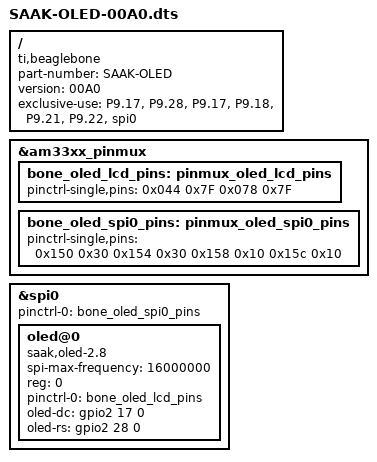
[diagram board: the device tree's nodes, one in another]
/*  
* Copyright (C) 2012 Texas Instruments Incorporated - http://www.ti.com/
*
* This program is free software; you can redistribute it and/or modify
* it under the terms of the GNU General Purpose License Version 2 as
* published by the Free Software Foundation
*
* by Saak Dertadian (s.dertadian@gmail.com)
*
* Cape Oled 2.8' for Beaglebone
* usind Oled 256x64 (Newhaven: NHD‐2.8‐25664UMB2)
*
*/

/dts-v1/;
/plugin/;

/ {
	compatible = "ti,beaglebone", "ti,beaglebone-black";

	/* identification */
	part-number = "SAAK-OLED";
	version = "00A0";

	/* state the resources this cape uses */
	exclusive-use =
		/* the pin header uses */
		"P9.17",	/* GPIO_DC */
		"P9.28",	/* GPIO_RS */
		"P9.17",	/* spi0_cs0 */
		"P9.18",	/* spi0_d1 */
		"P9.21",	/* spi0_d0 */
		"P9.22",	/* spi0_sclk */
		/* the hardware ip uses */
		"spi0";

	fragment@0
	{
		target = <&am33xx_pinmux>;
		__overlay__
		{
			bone_oled_lcd_pins: pinmux_oled_lcd_pins
			{
				pinctrl-single,pins = <
					0x044 0x7F  /* P9_23  49  OUTPUT MODE7 - DC  GPIO1-17 */
					0x078 0x7F  /* P9_12  60  OUTPUT MODE7 - RS  GPIO1_28 */
								
					/* OUTPUT  GPIO(mode7) 0x07 pulldown, 0x17 pullup, 0x?f no pullup/down */
					/* INPUT   GPIO(mode7) 0x27 pulldown, 0x37 pullup, 0x?f no pullup/down */
				>;
			};
			bone_oled_spi0_pins: pinmux_oled_spi0_pins
			{
				pinctrl-single,pins = <
					0x150 0x30  /* spi0_sclk, INPUT_PULLUP  | MODE0 */
					0x154 0x30  /* spi0_d0,   INPUT_PULLUP  | MODE0 */
					0x158 0x10  /* spi0_d1,   OUTPUT_PULLUP | MODE0 */
					0x15c 0x10  /* spi0_cs0,  OUTPUT_PULLUP | MODE0 */
				>;
			};
		};
	};

	fragment@1
	{
		target = <&spi0>;
		__overlay__
		{
			#address-cells = <1>;
			#size-cells = <0>;

			status = "okay";
			pinctrl-names = "default";
			pinctrl-0 = <&bone_oled_spi0_pins>;

			oled@0
			{
				#address-cells = <1>;
				#size-cells = <0>;

				compatible = "saak,oled-2.8";
				spi-max-frequency = <16000000>;
				reg = <0>;

				pinctrl-names = "default";
				pinctrl-0 = <&bone_oled_lcd_pins>;

				oled-dc = <&gpio2 17 0>;
				oled-rs = <&gpio2 28 0>;
			};
		};
	};
};
